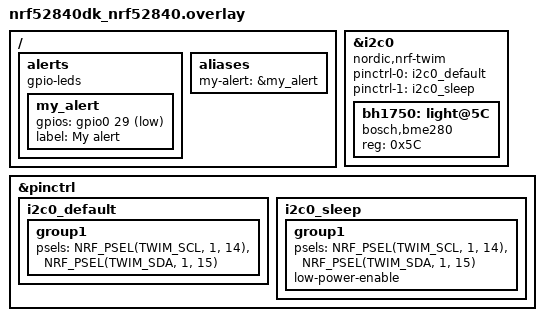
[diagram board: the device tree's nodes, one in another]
// To get started, press Ctrl+Space (or Option+Esc) to bring up the completion menu and view the available nodes.

// You can also use the buttons in the sidebar to perform actions on nodes.
// Actions currently available include:

// * Enabling / disabling the node
// * Adding the bus to a bus
// * Removing the node
// * Connecting ADC channels

// For more help, browse the DeviceTree documentation at https: //docs.zephyrproject.org/latest/guides/dts/index.html
// You can also visit the nRF DeviceTree extension documentation at https: //docs.nordicsemi.com/bundle/nrf-connect-vscode/page/guides/ncs_configure_app.html#devicetree-support-in-the-extension

&i2c0 {
    status = "okay";
    compatible = "nordic,nrf-twim";
    pinctrl-0 = <&i2c0_default>;
    pinctrl-1 = <&i2c0_sleep>;
    pinctrl-names = "default", "sleep";
    bh1750: light@5C {
        compatible = "bosch,bme280";
        status = "okay";
        reg = <0x5C>;
    };
};

&pinctrl {
    /omit-if-no-ref/ i2c0_default: i2c0_default {
        group1  {
            psels = <NRF_PSEL(TWIM_SCL, 1, 14)>,
                    <NRF_PSEL(TWIM_SDA, 1, 15)>;
        };
    };

    /omit-if-no-ref/ i2c0_sleep: i2c0_sleep {
        group1  {
            psels = <NRF_PSEL(TWIM_SCL, 1, 14)>,
                    <NRF_PSEL(TWIM_SDA, 1, 15)>;
            low-power-enable;
        };
    };
};

/ {
    alerts {

        compatible = "gpio-leds";

        my_alert: my_alert {
            gpios = <&gpio0 29 GPIO_ACTIVE_LOW>;
            label = "My alert";
        };


    };
    aliases {
        my-alert = &my_alert;
    };
};
